# MSPM0G121X register map
Vendor: Texas Instruments; File version: Revised: 2025-10-06 10:58:04
CPU: CM0 r0p1, little endian, MPU, no FPU, 3 interrupt priority bits
Registers are 32-bit, read-write, reset 0x0 unless marked. A register's access mark holds for its fields unless they carry their own. Offsets are from the block's base; [hi:lo] are bit positions; lines under a group give offsets from that group; {n}, {i} and the like mark numbered series; 'fields as' and 'values as' point back to an identical list.

## ADC0 — PERIPHERALREGION
Base 0x40004000
0x400 ADC0_FSUB_0 — Subscriber Configuration Register.
  [3:0] CHANID — 0 = disconnected. 1-15 = connected to channelID = CHANID.
    0=UNCONNECTED (A value of 0 specifies that the event is not connected)
0x444 ADC0_FPUB_1 — Publisher Configuration Register.
  fields as ADC0_FSUB_0
{0x800+0x18*i} ADC0_GPRCM[{i}] (i=0..0) group
  0x00 ADC0_PWREN — Power enable
    [0] ENABLE — Enable the power
      0=DISABLE (Disable Power); 1=ENABLE (Enable Power)
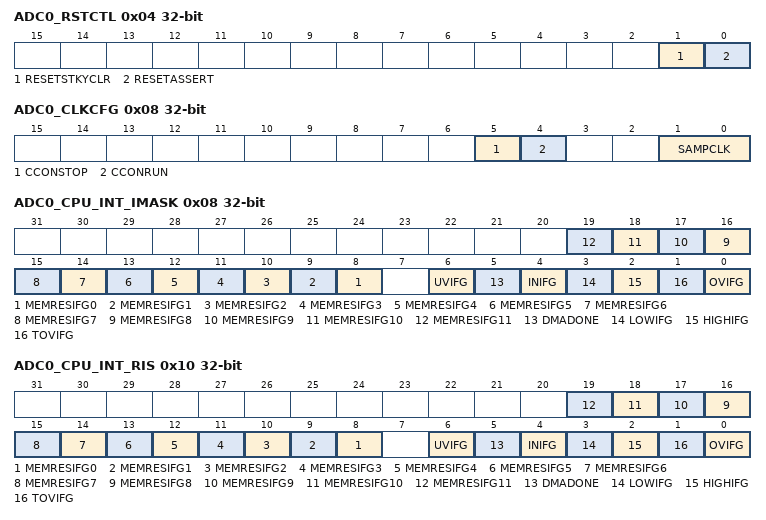
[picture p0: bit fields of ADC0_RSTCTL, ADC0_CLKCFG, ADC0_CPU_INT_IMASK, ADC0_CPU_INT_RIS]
  0x04 ADC0_RSTCTL wo — Reset Control
    [1] RESETSTKYCLR — Clear the RESETSTKY bit in the STAT register
      0=NOP (Writing 0 has no effect); 1=CLR (Clear reset sticky bit)
    [0] RESETASSERT — Assert reset to the peripheral
      0=NOP (Writing 0 has no effect); 1=ASSERT (Assert reset)
  0x08 ADC0_CLKCFG — ADC clock configuration Register
    [5] CCONSTOP — CCONSTOP: Forces SYSOSC to run at base frequency when device is in STOP mode which can be used as ADC sample or conversion clock source.
      0=DISABLE (ADC conversion clock source is not kept continuously on during STOP mode.); 1=ENABLE (ADC conversion clock source kept continuously on during STOP mode.)
    [4] CCONRUN — CCONRUN: Forces SYSOSC to run at base frequency when device is in RUN mode which can be used as ADC sample or conversion clock source.
      0=DISABLE (ADC conversion clock source is not kept continuously on during RUN mode.); 1=ENABLE (ADC conversion clock source kept continuously on during RUN mode.)
    [1:0] SAMPCLK — ADC sample clock source selection.
      0=ULPCLK (ULPCLK is the source of ADC sample clock.); 1=SYSOSC (SYSOSC is the source of ADC sample clock.); 2=HFCLK (HFCLK clock is the source of ADC sample clock. Note : HFCLK may not be available on all the devices.)
  0x14 ADC0_STAT ro — Status Register
    [16] RESETSTKY — This bit indicates, if the peripheral was reset, since this bit was cleared by RESETSTKYCLR in the RSTCTL register
      0=NORES (The peripheral has not been reset since this bit was last cleared by RESETSTKYCLR in the RSTCTL register); 1=RESET (The peripheral was reset since the last bit clear)
{0x1020+0x2C*i} ADC0_CPU_INT[{i}] (i=0..0) group
  0x00 ADC0_CPU_INT_IIDX ro — Interrupt index
    [9:0] STAT — Interrupt index status
      0=NO_INTR (No bit is set means there is no pending interrupt request); 1=OVIFG (MEMRESx overflow interrupt); 2=TOVIFG (Sequence Conversion time overflow interrupt); 3=HIGHIFG (High threshold compare interrupt); 4=LOWIFG (Low threshold compare interrupt); 5=INIFG (Primary Sequence In range comparator interrupt); 6=DMADONE (DMA done interrupt, generated on DMA transfer completion,); 7=UVIFG (MEMRESx underflow interrupt); {v}=MEMRESIFG{v-9} (MEMRES{v-9} data loaded interrupt) (v=9..32)
  0x08 ADC0_CPU_INT_IMASK — Interrupt mask
    [n+8] MEMRESIFG{n} (n=0..11) — Raw interrupt status for MEMRES{n}. This bit is set to 1 when MEMRES{n} is loaded with a new conversion result. Reading MEMRES{n} register will clear this bit, or when the corresponding bit in ICLR is set to 1
      0=CLR (No new data ready.); 1=SET (A new data is ready to be read.)
    [6] UVIFG — Raw interrupt flag for MEMRESx underflow. This bit is reset to 0 by IIDX read or when corresponding bit in ICLR is set to 1.
      0=CLR (Interrupt is not pending.); 1=SET (Interrupt is pending.)
    [5] DMADONE — Raw interrupt flag for DMADONE. This bit is reset to 0 by IIDX read or when corresponding bit in ICLR_EX is set to 1.
      values as UVIFG
    [4] INIFG — Mask INIFG in MIS_EX register.
      values as UVIFG
    [3] LOWIFG — Raw interrupt flag for the MEMRESx result register being below than the WCLOWx threshold of the window comparator. This bit is reset to 0 by IIDX read or when corresponding bit in ICLR_EX is set to 1.
      values as UVIFG
    [2] HIGHIFG — Raw interrupt flag for the MEMRESx result register being higher than the WCHIGHx threshold of the window comparator. This bit is reset to 0 by IIDX read or when corresponding bit in ICLR_EX is set to 1.
      values as UVIFG
    [1] TOVIFG — Raw interrupt flag for sequence conversion timeout overflow. This bit is reset to 0 by IIDX read or when corresponding bit in ICLR_EX is set to 1.
      values as UVIFG
    [0] OVIFG — Raw interrupt flag for MEMRESx overflow. This bit is reset to 0 by IIDX read or when corresponding bit in ICLR_EX is set to 1.
      values as UVIFG
  0x10 ADC0_CPU_INT_RIS ro — Raw interrupt status
    [n+8] MEMRESIFG{n} (n=0..11) — Raw interrupt status for MEMRES{n}. This bit is set to 1 when MEMRES{n} is loaded with a new conversion result. Reading MEMRES{n} register will clear this bit, or when the corresponding bit in ICLR is set to 1
      values as ADC0_CPU_INT[0].ADC0_CPU_INT_IMASK.MEMRESIFG0
    [6] UVIFG — Raw interrupt flag for MEMRESx underflow. This bit is reset to 0 by IIDX read or when corresponding bit in ICLR is set to 1.
      values as ADC0_CPU_INT[0].ADC0_CPU_INT_IMASK.UVIFG
    [5] DMADONE — Raw interrupt flag for DMADONE. This bit is reset to 0 by IIDX read or when corresponding bit in ICLR_EX is set to 1.
      values as ADC0_CPU_INT[0].ADC0_CPU_INT_IMASK.UVIFG
    [4] INIFG — Mask INIFG in MIS_EX register.
      values as ADC0_CPU_INT[0].ADC0_CPU_INT_IMASK.UVIFG
    [3] LOWIFG — Raw interrupt flag for the MEMRESx result register being below than the WCLOWx threshold of the window comparator. This bit is reset to 0 by IIDX read or when corresponding bit in ICLR_EX is set to 1.
      values as ADC0_CPU_INT[0].ADC0_CPU_INT_IMASK.UVIFG
    [2] HIGHIFG — Raw interrupt flag for the MEMRESx result register being higher than the WCHIGHx threshold of the window comparator. This bit is reset to 0 by IIDX read or when corresponding bit in ICLR_EX is set to 1.
      values as ADC0_CPU_INT[0].ADC0_CPU_INT_IMASK.UVIFG
    [1] TOVIFG — Raw interrupt flag for sequence conversion trigger overflow. This bit is reset to 0 by IIDX read or when corresponding bit in ICLR_EX is set to 1.
      values as ADC0_CPU_INT[0].ADC0_CPU_INT_IMASK.UVIFG
    [0] OVIFG — Raw interrupt flag for MEMRESx overflow. This bit is reset to 0 by IIDX read or when corresponding bit in ICLR_EX is set to 1.
      values as ADC0_CPU_INT[0].ADC0_CPU_INT_IMASK.UVIFG
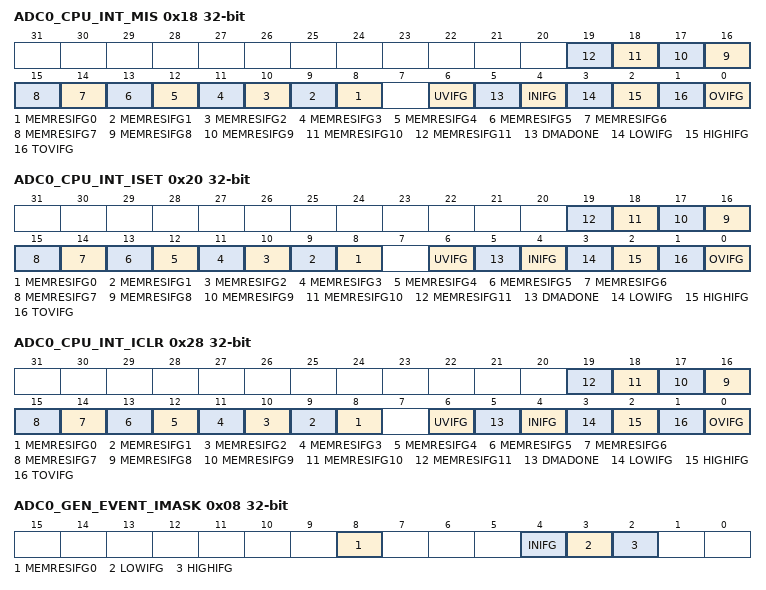
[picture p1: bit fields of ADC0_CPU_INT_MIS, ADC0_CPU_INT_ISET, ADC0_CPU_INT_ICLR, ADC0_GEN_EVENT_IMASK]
  0x18 ADC0_CPU_INT_MIS ro — Masked interrupt status
    fields as ADC0_CPU_INT[0].ADC0_CPU_INT_IMASK
  0x20 ADC0_CPU_INT_ISET wo — Interrupt set
    [n+8] MEMRESIFG{n} (n=0..11) — Raw interrupt status for MEMRES{n}. This bit is set to 1 when MEMRES{n} is loaded with a new conversion result. Reading MEMRES{n} register will clear this bit, or when the corresponding bit in ICLR is set to 1
      0=NO_EFFECT (No new data ready.); 1=SET (A new data is ready to be read.)
    [6] UVIFG — Raw interrupt flag for MEMRESx underflow. This bit is reset to 0 by IIDX read or when corresponding bit in ICLR_EX is set to 1.
      0=NO_EFFECT (Interrupt is not pending.); 1=SET (Interrupt is pending.)
    [5] DMADONE — Raw interrupt flag for DMADONE. This bit is reset to 0 by IIDX read or when corresponding bit in ICLR_EX is set to 1.
      values as UVIFG
    [4] INIFG — Mask INIFG in MIS_EX register.
      values as UVIFG
    [3] LOWIFG — Raw interrupt flag for the MEMRESx result register being below than the WCLOWx threshold of the window comparator. This bit is reset to 0 by IIDX read or when corresponding bit in ICLR_EX is set to 1.
      values as UVIFG
    [2] HIGHIFG — Raw interrupt flag for the MEMRESx result register being higher than the WCHIGHx threshold of the window comparator. This bit is reset to 0 by IIDX read or when corresponding bit in ICLR_EX is set to 1.
      values as UVIFG
    [1] TOVIFG — Raw interrupt flag for sequence conversion timeout overflow. This bit is reset to 0 by IIDX read or when corresponding bit in ICLR_EX is set to 1.
      values as UVIFG
    [0] OVIFG — Raw interrupt flag for MEMRESx overflow. This bit is reset to 0 by IIDX read or when corresponding bit in ICLR_EX is set to 1.
      values as UVIFG
  0x28 ADC0_CPU_INT_ICLR wo — Interrupt clear
    [n+8] MEMRESIFG{n} (n=0..11) — Raw interrupt status for MEMRES{n}. This bit is set to 1 when MEMRES{n} is loaded with a new conversion result. Reading MEMRES{n} register will clear this bit, or when the corresponding bit in ICLR is set to 1
      0=NO_EFFECT (No new data ready.); 1=CLR (A new data is ready to be read.)
    [6] UVIFG — Raw interrupt flag for MEMRESx underflow. This bit is reset to 0 by IIDX read or when corresponding bit in ICLR_EX is set to 1.
      0=NO_EFFECT (Interrupt is not pending.); 1=CLR (Interrupt is pending.)
    [5] DMADONE — Raw interrupt flag for DMADONE. This bit is reset to 0 by IIDX read or when corresponding bit in ICLR_EX is set to 1.
      values as UVIFG
    [4] INIFG — Mask INIFG in MIS_EX register.
      values as UVIFG
    [3] LOWIFG — Raw interrupt flag for the MEMRESx result register being below than the WCLOWx threshold of the window comparator. This bit is reset to 0 by IIDX read or when corresponding bit in ICLR_EX is set to 1.
      values as UVIFG
    [2] HIGHIFG — Raw interrupt flag for the MEMRESx result register being higher than the WCHIGHx threshold of the window comparator. This bit is reset to 0 by IIDX read or when corresponding bit in ICLR_EX is set to 1.
      values as UVIFG
    [1] TOVIFG — Raw interrupt flag for sequence conversion timeout overflow. This bit is reset to 0 by IIDX read or when corresponding bit in ICLR_EX is set to 1.
      values as UVIFG
    [0] OVIFG — Raw interrupt flag for MEMRESx overflow. This bit is reset to 0 by IIDX read or when corresponding bit in ICLR_EX is set to 1.
      values as UVIFG
{0x1050+0x2C*i} ADC0_GEN_EVENT[{i}] (i=0..0) group
  0x00 ADC0_GEN_EVENT_IIDX ro — Interrupt index
    [9:0] STAT — Interrupt index status
      0=NO_INTR (No bit is set means there is no pending interrupt request); 3=HIGHIFG (High threshold compare interrupt); 4=LOWIFG (Low threshold compare interrupt); 5=INIFG (Primary Sequence In range comparator interrupt); 9=MEMRESIFG0 (MEMRES0 data loaded interrupt)
  0x08 ADC0_GEN_EVENT_IMASK — Interrupt mask
    [8] MEMRESIFG0 — Raw interrupt status for MEMRES0. This bit is set to 1 when MEMRES0 is loaded with a new conversion result. Reading MEMRES0 register will clear this bit, or when the corresponding bit in ICLR is set to 1
      values as ADC0_CPU_INT[0].ADC0_CPU_INT_IMASK.MEMRESIFG0
    [4] INIFG — Mask INIFG in MIS_EX register.
      values as ADC0_CPU_INT[0].ADC0_CPU_INT_IMASK.UVIFG
    [3] LOWIFG — Raw interrupt flag for the MEMRESx result register being below than the WCLOWx threshold of the window comparator. This bit is reset to 0 by IIDX read or when corresponding bit in ICLR_EX is set to 1.
      values as ADC0_CPU_INT[0].ADC0_CPU_INT_IMASK.UVIFG
    [2] HIGHIFG — Raw interrupt flag for the MEMRESx result register being higher than the WCHIGHx threshold of the window comparator. This bit is reset to 0 by IIDX read or when corresponding bit in ICLR_EX is set to 1.
      values as ADC0_CPU_INT[0].ADC0_CPU_INT_IMASK.UVIFG
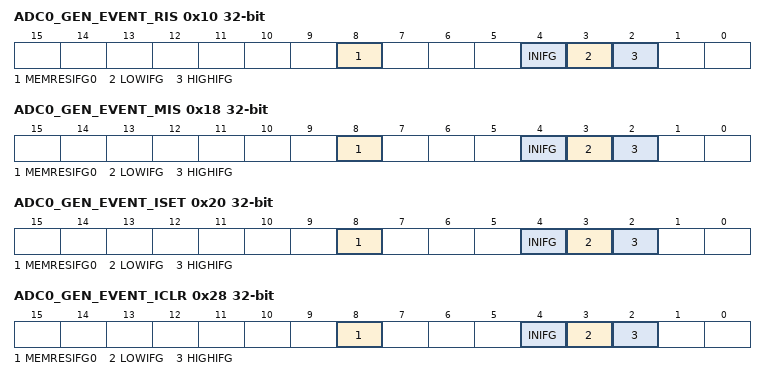
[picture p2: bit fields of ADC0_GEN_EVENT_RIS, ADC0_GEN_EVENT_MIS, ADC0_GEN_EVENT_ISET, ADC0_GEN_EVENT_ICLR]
  0x10 ADC0_GEN_EVENT_RIS ro — Raw interrupt status
    fields as ADC0_GEN_EVENT[0].ADC0_GEN_EVENT_IMASK
  0x18 ADC0_GEN_EVENT_MIS ro — Masked interrupt status
    fields as ADC0_GEN_EVENT[0].ADC0_GEN_EVENT_IMASK
  0x20 ADC0_GEN_EVENT_ISET wo — Interrupt set
    [8] MEMRESIFG0 — Raw interrupt status for MEMRES0. This bit is set to 1 when MEMRES0 is loaded with a new conversion result. Reading MEMRES0 register will clear this bit, or when the corresponding bit in ICLR is set to 1
      values as ADC0_CPU_INT[0].ADC0_CPU_INT_ISET.MEMRESIFG0
    [4] INIFG — Mask INIFG in MIS_EX register.
      values as ADC0_CPU_INT[0].ADC0_CPU_INT_ISET.UVIFG
    [3] LOWIFG — Raw interrupt flag for the MEMRESx result register being below than the WCLOWx threshold of the window comparator. This bit is reset to 0 by IIDX read or when corresponding bit in ICLR_EX is set to 1.
      values as ADC0_CPU_INT[0].ADC0_CPU_INT_ISET.UVIFG
    [2] HIGHIFG — Raw interrupt flag for the MEMRESx result register being higher than the WCHIGHx threshold of the window comparator. This bit is reset to 0 by IIDX read or when corresponding bit in ICLR_EX is set to 1.
      values as ADC0_CPU_INT[0].ADC0_CPU_INT_ISET.UVIFG
  0x28 ADC0_GEN_EVENT_ICLR wo — Interrupt clear
    [8] MEMRESIFG0 — Raw interrupt status for MEMRES0. This bit is set to 1 when MEMRES0 is loaded with a new conversion result. Reading MEMRES0 register will clear this bit, or when the corresponding bit in ICLR is set to 1
      values as ADC0_CPU_INT[0].ADC0_CPU_INT_ICLR.MEMRESIFG0
    [4] INIFG — Mask INIFG in MIS_EX register.
      values as ADC0_CPU_INT[0].ADC0_CPU_INT_ICLR.UVIFG
    [3] LOWIFG — Raw interrupt flag for the MEMRESx result register being below than the WCLOWx threshold of the window comparator. This bit is reset to 0 by IIDX read or when corresponding bit in ICLR_EX is set to 1.
      values as ADC0_CPU_INT[0].ADC0_CPU_INT_ICLR.UVIFG
    [2] HIGHIFG — Raw interrupt flag for the MEMRESx result register being higher than the WCHIGHx threshold of the window comparator. This bit is reset to 0 by IIDX read or when corresponding bit in ICLR_EX is set to 1.
      values as ADC0_CPU_INT[0].ADC0_CPU_INT_ICLR.UVIFG
{0x1080+0x2C*i} ADC0_DMA_TRIG[{i}] (i=0..0) group
  0x00 ADC0_DMA_TRIG_IIDX ro — Interrupt index
    [9:0] STAT — Interrupt index status
      0=NO_INTR (No bit is set means there is no pending interrupt request); {v}=MEMRESIFG{v-9} (MEMRES{v-9} data loaded interrupt) (v=9..32)
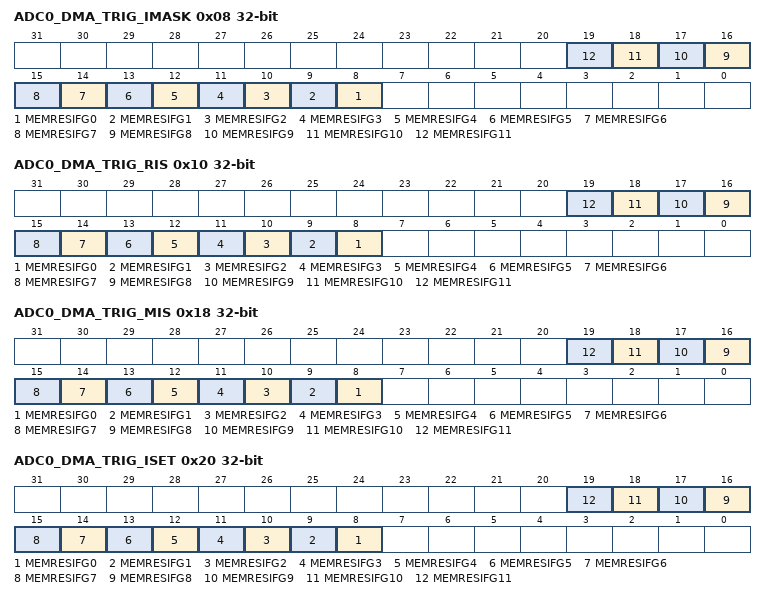
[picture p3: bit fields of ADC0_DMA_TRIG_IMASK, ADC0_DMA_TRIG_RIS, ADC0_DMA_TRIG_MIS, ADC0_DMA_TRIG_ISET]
  0x08 ADC0_DMA_TRIG_IMASK — Interrupt mask extension
    [all] fields
      values as ADC0_CPU_INT[0].ADC0_CPU_INT_IMASK.MEMRESIFG0
    [n+8] MEMRESIFG{n} (n=0..11) — Raw interrupt status for MEMRES{n}. This bit is set to 1 when MEMRES{n} is loaded with a new conversion result. Reading MEMRES{n} register will clear this bit, or when the corresponding bit in ICLR is set to 1
  0x10 ADC0_DMA_TRIG_RIS ro — Raw interrupt status extension
    fields as ADC0_DMA_TRIG[0].ADC0_DMA_TRIG_IMASK
  0x18 ADC0_DMA_TRIG_MIS ro — Masked interrupt status extension
    fields as ADC0_DMA_TRIG[0].ADC0_DMA_TRIG_IMASK
  0x20 ADC0_DMA_TRIG_ISET wo — Interrupt set extension
    [all] fields
      values as ADC0_CPU_INT[0].ADC0_CPU_INT_ISET.MEMRESIFG0
    [n+8] MEMRESIFG{n} (n=0..11) — Raw interrupt status for MEMRES{n}. This bit is set to 1 when MEMRES{n} is loaded with a new conversion result. Reading MEMRES{n} register will clear this bit, or when the corresponding bit in ICLR is set to 1
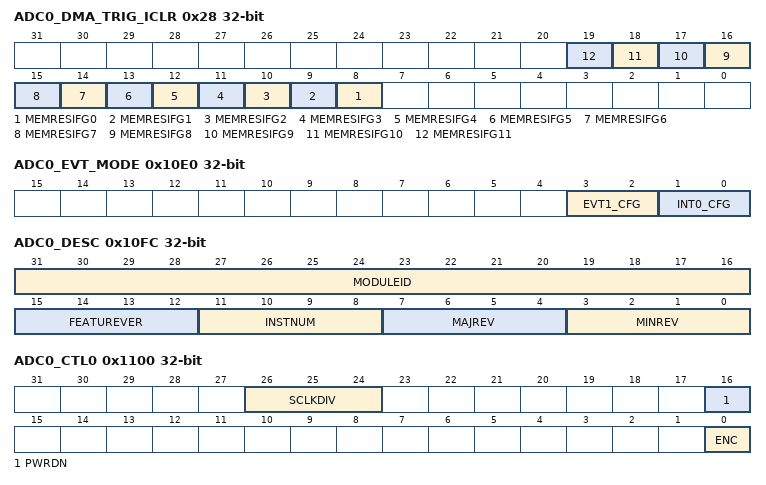
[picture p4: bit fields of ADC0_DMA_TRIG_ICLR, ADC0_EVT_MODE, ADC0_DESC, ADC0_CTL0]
  0x28 ADC0_DMA_TRIG_ICLR wo — Interrupt clear extension
    [all] fields
      values as ADC0_CPU_INT[0].ADC0_CPU_INT_ICLR.MEMRESIFG0
    [n+8] MEMRESIFG{n} (n=0..11) — Raw interrupt status for MEMRES{n}. This bit is set to 1 when MEMRES{n} is loaded with a new conversion result. Reading MEMRES{n} register will clear this bit, or when the corresponding bit in ICLR is set to 1
0x10E0 ADC0_EVT_MODE ro — Event Mode
  [3:2] EVT1_CFG — Event line mode select for event corresponding to GEN_EVENT
    0=DISABLE (The interrupt or event line is disabled.); 1=SOFTWARE (The interrupt or event line is in software mode. Software must clear the RIS.); 2=HARDWARE (The interrupt or event line is in hardware mode. The hardware (another module) clears automatically the associated RIS flag.)
  [1:0] INT0_CFG — Event line mode select for event corresponding to CPU_INT
    values as EVT1_CFG
0x10FC ADC0_DESC ro — Module Description
  [31:16] MODULEID — Module identification contains a unique peripheral identification number. The assignments are maintained in a central database for all of the platform modules to ensure uniqueness.
  [15:12] FEATUREVER — Feature Set for the module *instance*
  [11:8] INSTNUM — Instance Number within the device. This will be a parameter to the RTL for modules that can have multiple instances
  [7:4] MAJREV — Major rev of the IP
  [3:0] MINREV — Minor rev of the IP
0x1100 ADC0_CTL0 — Control Register 0
  [26:24] SCLKDIV — Sample clock divider
    0=DIV_BY_1 (Do not divide clock source); 1=DIV_BY_2 (Divide clock source by 2); 2=DIV_BY_4 (Divide clock source by 4); 3=DIV_BY_8 (Divide clock source by 8); 4=DIV_BY_16 (Divide clock source by 16); 5=DIV_BY_24 (Divide clock source by 24); 6=DIV_BY_32 (Divide clock source by 32); 7=DIV_BY_48 (Divide clock source by 48)
  [16] PWRDN — Power down policy
    0=AUTO (ADC is powered down on completion of a conversion if there is no pending trigger); 1=MANUAL (ADC remains powered on as long as it is enabled through software.)
  [0] ENC — Enable conversion
    0=OFF (Conversion disabled. ENC change from ON to OFF will abort single or repeat sequence on a MEMCTLx boundary. The current conversion will finish and result stored in corresponding MEMRESx.); 1=ON (Conversion enabled. ADC sequencer waits for valid trigger (software or hardware).)
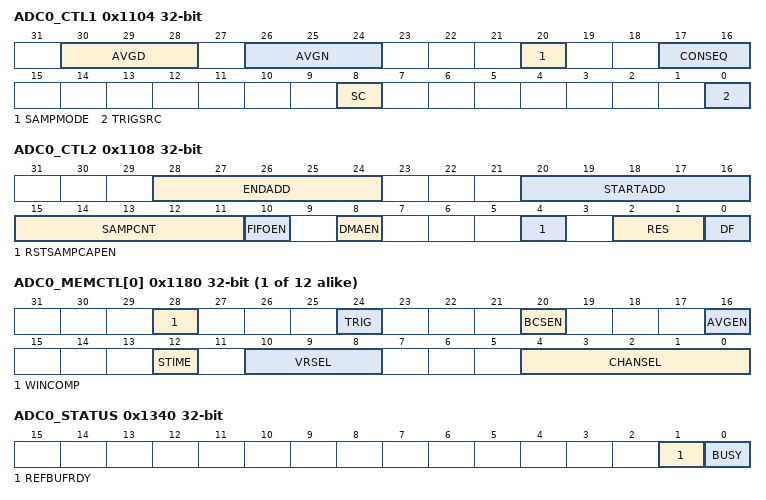
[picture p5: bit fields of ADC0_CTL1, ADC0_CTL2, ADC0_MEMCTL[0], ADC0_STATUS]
0x1104 ADC0_CTL1 — Control Register 1
  [30:28] AVGD — Hardware averager denominator. The number to divide the accumulated value by (this is a shift). Note result register is maximum of 16-bits long so if not shifted appropriately result will be truncated.
    0=SHIFT0 (No shift); {v}=SHIFT{v} ({v} bit shift) (v=1..7)
  [26:24] AVGN — Hardware averager numerator. Selects number of conversions to accumulate for current MEMCTLx and then it is divided by AVGD. Result will be stored in MEMRESx.
    0=DISABLE (Disables averager); 1=AVG_2 (Averages 2 conversions before storing in MEMRESx register); 2=AVG_4 (Averages 4 conversions before storing in MEMRESx register); 3=AVG_8 (Averages 8 conversions before storing in MEMRESx register); 4=AVG_16 (Averages 16 conversions before storing in MEMRESx register); 5=AVG_32 (Averages 32 conversions before storing in MEMRESx register); 6=AVG_64 (Averages 64 conversions before storing in MEMRESx register); 7=AVG_128 (Averages 128 conversions before storing in MEMRESx register)
  [20] SAMPMODE — Sample mode. This bit selects the source of the sampling signal. MANUAL option is not valid when TRIGSRC is selected as hardware event trigger.
    0=AUTO (Sample timer high phase is used as sample signal); 1=MANUAL (Software trigger is used as sample signal)
  [17:16] CONSEQ — Conversion sequence mode
    0=SINGLE (ADC channel in MEMCTLx pointed by STARTADD will be converted once); 1=SEQUENCE (ADC channel sequence pointed by STARTADD and ENDADD will be converted once); 2=REPEATSINGLE (ADC channel in MEMCTLx pointed by STARTADD will be converted repeatedly); 3=REPEATSEQUENCE (ADC channel sequence pointed by STARTADD and ENDADD will be converted repeatedly)
  [8] SC — Start of conversion
    0=STOP (When SAMPMODE is set to MANUAL, clearing this bit will end the sample phase and the conversion phase will start. When SAMPMODE is set to AUTO, writing 0 has no effect.); 1=START (When SAMPMODE is set to MANUAL, setting this bit will start the sample phase. Sample phase will last as long as this bit is set. When SAMPMODE is set to AUTO, setting this bit will trigger the timer based sample time.)
  [0] TRIGSRC — Sample trigger source
    0=SOFTWARE (Software trigger); 1=EVENT (Hardware event trigger)
0x1108 ADC0_CTL2 — Control Register 2
  [28:24] ENDADD — Sequence end address. These bits select which MEMCTLx is the last one for the sequence mode. The value of ENDADD is 0x00 to 0x17, corresponding to MEMRES0 to MEMRES23.
    {v}=ADDR_{v:02} (MEMCTL{v} is selected as end address of sequence.) (v=0..23)
  [20:16] STARTADD — Sequencer start address. These bits select which MEMCTLx is used for single conversion or as first MEMCTL for sequence mode. The value of STARTADD is 0x00 to 0x17, corresponding to MEMRES0 to MEMRES23.
    {v}=ADDR_{v:02} (MEMCTL{v} is selected as start address of a sequence or for a single conversion.) (v=0..23)
  [15:11] SAMPCNT — Number of ADC converted samples to be transferred on a DMA trigger
    0=MIN (Minimum value); 24=MAX (Maximum value)
  [10] FIFOEN — Enable FIFO based operation
    0=DISABLE; 1=ENABLE
  [8] DMAEN — Enable DMA trigger for data transfer. Note: DMAEN bit is cleared by hardware based on DMA done signal at the end of data transfer. Software has to re-enable DMAEN bit for ADC to generate DMA triggers.
    0=DISABLE (DMA trigger not enabled); 1=ENABLE (DMA trigger enabled)
  [4] RSTSAMPCAPEN — 0: Sample and hold capacitor is not explicitly discharged at the end of conversion. 1: Sample and hold capacitor is discharged at the end of conversion. This incurs one additional conversion clock cycle.
    0=DISABLE (Disable sample capacitor discharge feature.); 1=ENABLE (Enable sample capacitor discharge feature.)
  [2:1] RES — Resolution. These bits define the resolution of ADC conversion result. Note : A value of 3 defaults to 12-bits resolution.
    0=BIT_12 (12-bits resolution); 1=BIT_10 (10-bits resolution); 2=BIT_8 (8-bits resolution)
  [0] DF — Data read-back format. Data is always stored in binary unsigned format.
    0=UNSIGNED (Digital result reads as Binary Unsigned.); 1=SIGNED (Digital result reads Signed Binary. (2s complement), left aligned.)
0x1110 ADC0_CLKFREQ — Sample Clock Frequency Range Register
  [2:0] FRANGE — Frequency Range.
    0=RANGE1TO4 (1 to 4 MHz); 1=RANGE4TO8 (>4 to 8 MHz); 2=RANGE8TO16 (>8 to 16 MHz); 3=RANGE16TO20 (>16 to 20 MHz); 4=RANGE20TO24 (>20 to 24 MHz); 5=RANGE24TO32 (>24 to 32 MHz); 6=RANGE32TO40 (>32 to 40 MHz); 7=RANGE40TO48 (>40 to 48 MHz)
0x1114 ADC0_SCOMP0 — Sample Time Compare 0 Register
  [9:0] VAL — Specifies the number of sample clocks. When VAL = 0 or 1, number of sample clocks = Sample clock divide value. When VAL > 1, number of sample clocks = VAL x Sample clock divide value. Note: Sample clock divide value is not the value written to SCLKDIV but the actual divide value (SCLKDIV = 2 implies divide value is 4). Example: VAL = 4, SCLKDIV = 3 implies 32 sample clock cycles.
0x1118 ADC0_SCOMP1 — Sample Time Compare 1 Register
  fields as ADC0_SCOMP0
0x1148 ADC0_WCLOW — Window Comparator Low Threshold Register
  [15:0] DATA — If DF = 0, unsigned binary format has to be used. The value based on the resolution has to be right aligned with the MSB on the left. For 10-bits and 8-bits resolution, unused bits have to be 0s. If DF = 1, 2s-complement format has to be used. The value based on the resolution has to be left aligned with the LSB on the right. For 10-bits and 8-bits resolution, unused bits have to be 0s.
0x1150 ADC0_WCHIGH — Window Comparator High Threshold Register
  [15:0] DATA — If DF = 0, unsigned binary format has to be used. The threshold value has to be right aligned, with the MSB on the left. For 10-bits and 8-bits resolution, unused bit have to be 0s. If DF = 1, 2s-complement format has to be used. The value based on the resolution has to be left aligned with the LSB on the right. For 10-bits and 8-bits resolution, unused bit have to be 0s.
{0x1180+4i} ADC0_MEMCTL[{i}] (i=0..11) — Conversion Memory Control Register
  [28] WINCOMP — Enable window comparator.
    0=DISABLE; 1=ENABLE
  [24] TRIG — Trigger policy. Indicates if a trigger will be needed to step to the next MEMCTL in the sequence or to perform next conversion in the case of repeat single channel conversions.
    0=AUTO_NEXT (Next conversion is automatic); 1=TRIGGER_NEXT (Next conversion requires a trigger)
  [20] BCSEN — Enable burn out current source.
    0=DISABLE; 1=ENABLE
  [16] AVGEN — Enable hardware averaging.
    0=DISABLE (Averaging disabled.); 1=ENABLE (Averaging enabled.)
  [12] STIME — Selects the source of sample timer period between SCOMP0 and SCOMP1.
    0=SEL_SCOMP0 (Select SCOMP0); 1=SEL_SCOMP1 (Select SCOMP1)
  [10:8] VRSEL — Voltage reference selection. VEREFM must be connected to on-board ground when external reference option is selected. Note: Writing value 0x3 defaults to INTREF.
    0=VDDA_VSSA (VDDA reference); 1=EXTREF_VREFM (External reference from pin); 2=INTREF_VSSA (Internal reference); 3=VDDA_VREFM (VDDA and VREFM connected to VREF+ and VREF- of ADC); 4=INTREF_VREFM (INTREF and VREFM connected to VREF+ and VREF- of ADC)
  [4:0] CHANSEL — Input channel select.
    {v}=CHAN_{v} (Selects channel {v}) (v=0..31)
0x1340 ADC0_STATUS ro — Status Register
  [1] REFBUFRDY — Indicates reference buffer is powered up and ready.
    0=NOTREADY; 1=READY
  [0] BUSY — Busy. This bit indicates that an active ADC sample or conversion operation is in progress.
    0=IDLE (No ADC sampling or conversion in progress.); 1=ACTIVE (ADC sampling or conversion is in progress.)

## ADC1 — PERIPHERALREGION
Base 0x40006000
Registers as ADC0 (with ADC0 read as ADC1).
